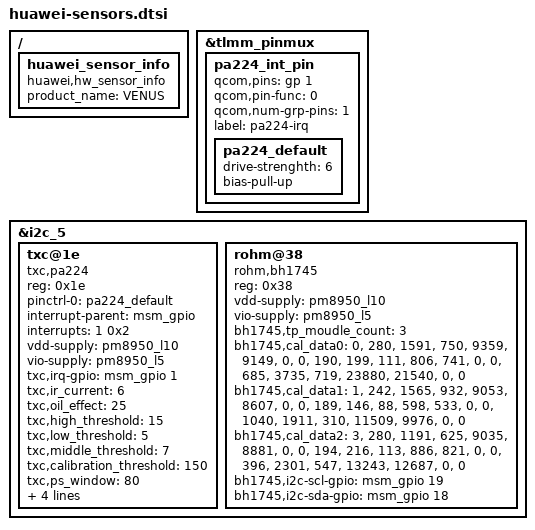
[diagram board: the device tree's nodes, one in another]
/*use fromdos convert file format to linux*/
/* Copyright (c) 2013 The Linux Foundation. All rights reserved.
 *
 * This program is free software; you can redistribute it and/or modify
 * it under the terms of the GNU General Public License version 2 and
 * only version 2 as published by the Free Software Foundation.
 *
 * This program is distributed in the hope that it will be useful,
 * but WITHOUT ANY WARRANTY; without even the implied warranty of
 * MERCHANTABILITY or FITNESS FOR A PARTICULAR PURPOSE.  See the
 * GNU General Public License for more details.
 */
&tlmm_pinmux {
	pa224_int_pin {
		qcom,pins = <&gp 1>;
		qcom,pin-func = <0>;
		qcom,num-grp-pins = <1>;
		label = "pa224-irq";
		pa224_default: pa224_default {
			drive-strenghth = <6>;
			bias-pull-up;
		};
	};
};

&i2c_5{
	txc@1e {
		compatible = "txc,pa224";
		reg = <0x1e>;
		pinctrl-names = "default";
		pinctrl-0 = <&pa224_default>;
		interrupt-parent = <&msm_gpio>;
		interrupts = <1 0x2>;
		vdd-supply = <&pm8950_l10>;
		vio-supply = <&pm8950_l5>;
		txc,irq-gpio = <&msm_gpio 1 0x2>;
		/*IR CURRENT 10MA*/
		txc,ir_current = <6>;
		txc,oil_effect = <25>;
		txc,high_threshold = <15>;
		txc,low_threshold = <5>;
		txc,middle_threshold = <7>;
		txc,calibration_threshold = <150>;
		txc,ps_window = <80>;
		txc,ps_wave = <40>;
		txc,ps_defalt_crosstalk = <50>;
		txc,i2c-scl-gpio = <&msm_gpio 19 0x0>;
		txc,i2c-sda-gpio = <&msm_gpio 18 0x0>;
	};

	rohm@38 {
		compatible = "rohm,bh1745";
		reg = <0x38>;
		vdd-supply = <&pm8950_l10>;
		vio-supply = <&pm8950_l5>;
		bh1745,tp_moudle_count = <3>;
		/*[module_id] [golden judge] r[0] r[1] g[0] g[1] b[0] b[1]*/
		bh1745,cal_data0 = "0","280","1591","750","9359","9149","0","0",
		/*[white judge] r[0] r[1] g[0] g[1] b[0] b[1]*/
		"190","199","111","806","741","0","0",
		/*[black judge] r[0] r[1] g[0] g[1] b[0] b[1]*/
		"685","3735","719","23880","21540","0","0";
		/*[module_id] [golden judge] r[0] r[1] g[0] g[1] b[0] b[1]*/
		bh1745,cal_data1 = "1","242","1565","932","9053","8607","0","0",
		/*[white judge] r[0] r[1] g[0] g[1] b[0] b[1]*/
		"189","146","88","598","533","0","0",
		/*[black judge] r[0] r[1] g[0] g[1] b[0] b[1]*/
		"1040","1911","310","11509","9976","0","0";

		/*[module_id] [golden judge] r[0] r[1] g[0] g[1] b[0] b[1]*/
		bh1745,cal_data2 = "3","280","1191","625","9035","8881","0","0",
		/*[white judge] r[0] r[1] g[0] g[1] b[0] b[1]*/
		"194","216","113","886","821","0","0",
		/*[black judge] r[0] r[1] g[0] g[1] b[0] b[1]*/
		"396","2301","547","13243","12687","0","0";
		bh1745,i2c-scl-gpio = <&msm_gpio 19 0x0>;
		bh1745,i2c-sda-gpio = <&msm_gpio 18 0x0>;
	};
};

 / {
	huawei_sensor_info {
		compatible = "huawei,hw_sensor_info";
		product_name = "VENUS";
	};
};

